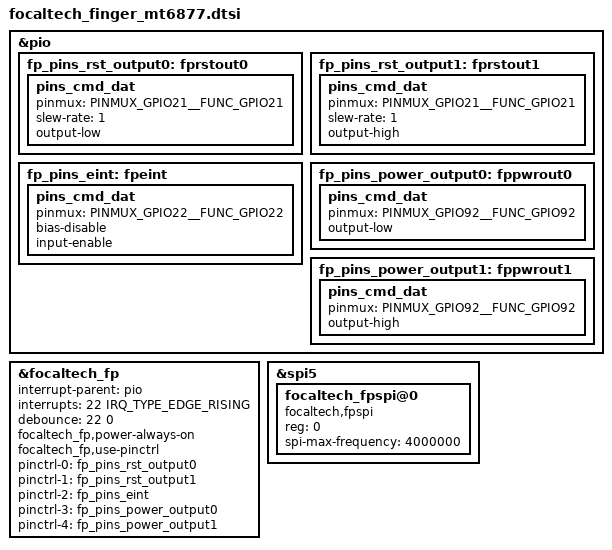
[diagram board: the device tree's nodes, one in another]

/* focaltech fingerprint ctrl start */

&pio {
	fp_pins_rst_output0: fprstout0{
		    pins_cmd_dat {
			pinmux = <PINMUX_GPIO21__FUNC_GPIO21>;
			slew-rate = <1>;
			output-low;
		};
	};
	fp_pins_rst_output1: fprstout1{
		    pins_cmd_dat {
			pinmux = <PINMUX_GPIO21__FUNC_GPIO21>;
			slew-rate = <1>;
			output-high;
		};
	};
	fp_pins_eint: fpeint{
		pins_cmd_dat {
			pinmux = <PINMUX_GPIO22__FUNC_GPIO22>;
			bias-disable;
			input-enable;
		};
	};
	fp_pins_power_output0: fppwrout0{
		    pins_cmd_dat {
			pinmux = <PINMUX_GPIO92__FUNC_GPIO92>;
			output-low;
		};
	};
	fp_pins_power_output1: fppwrout1{
		    pins_cmd_dat {
			pinmux = <PINMUX_GPIO92__FUNC_GPIO92>;
			output-high;
		};
	};
};

&focaltech_fp{

	interrupt-parent = <&pio>;
	interrupts = <22 IRQ_TYPE_EDGE_RISING>;
	debounce = <22 0>;
	
	focaltech_fp,power-always-on;
	//focaltech_fp,use-regulator;
	//ff_vdd-supply = <&mt_pmic_vfp_ldo_reg>
	focaltech_fp,use-pinctrl;
	//focaltech_fp,read-chip;    //If you want to read the id please open this sentence
	
	pinctrl-names = "ff_pins_reset_low","ff_pins_reset_high","ff_pins_irq_as_int","ff_pins_power_low","ff_pins_power_high";
	pinctrl-0 = <&fp_pins_rst_output0>;
	pinctrl-1 = <&fp_pins_rst_output1>;
	pinctrl-2 = <&fp_pins_eint>;
	pinctrl-3 = <&fp_pins_power_output0>;
	pinctrl-4 = <&fp_pins_power_output1>;

	status = "okay";
};

&spi5 {
	focaltech_fpspi@0 {
		compatible = "focaltech,fpspi";
		reg = <0>;
		spi-max-frequency = <4000000>;
		status = "okay";
	};
};


/* focaltech fingerprint ctrl end */
